VERSION ""

NS_ :

BS_:

BU_: VCU Tester GWM

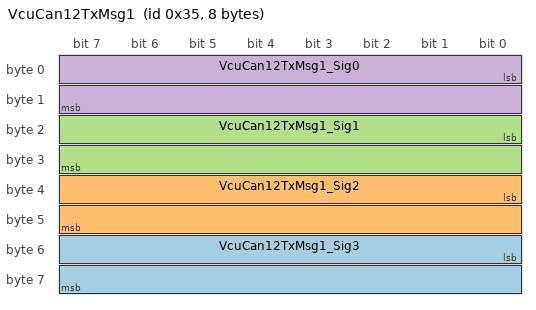
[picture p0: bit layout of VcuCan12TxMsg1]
BO_ 53 VcuCan12TxMsg1: 8 VCU
 SG_ VcuCan12TxMsg1_Sig3 : 48|16@1- (1,0) [0|0] ""  GWM
 SG_ VcuCan12TxMsg1_Sig2 : 32|16@1- (1,0) [0|0] ""  GWM
 SG_ VcuCan12TxMsg1_Sig1 : 16|16@1- (1,0) [0|0] ""  GWM
 SG_ VcuCan12TxMsg1_Sig0 : 0|16@1- (1,0) [0|0] ""  GWM

BO_ 2033 XCP_Response: 8 VCU
 SG_ XCP_Response_Signal : 0|64@1+ (1,0) [0|1.844674407371E+019] ""  Tester

BO_ 2032 XCP_Request: 8 Tester
 SG_ XCP_Request_Signal : 0|64@1+ (1,0) [0|1.844674407371E+019] ""  VCU

BA_DEF_ BO_  "VFrameFormat" ENUM  "StandardCAN","ExtendedCAN","reserved","reserved","reserved","reserved","reserved","reserved","reserved","reserved","reserved","reserved","reserved","reserved","StandardCAN_FD","ExtendedCAN_FD";
BA_DEF_ BO_  "GenMsgCycleTime" INT 0 0;
BA_DEF_ BO_  "GenMsgSendType" ENUM  "Cyclic","NotUsed","NotUsed","NotUsed","NotUsed","NotUsed","NotUsed","IfActive","NoMsgSendType","NotUsed";
BA_DEF_ SG_  "GenSigSendType" ENUM  "Cyclic","OnWrite","OnWriteWithRepetition","OnChange","OnChangeWithRepetition","IfActive","IfActiveWithRepetition","NoSigSendType","NotUsed","NotUsed","NotUsed","NotUsed","NotUsed";
BA_DEF_  "Baudrate" INT 0 1000000;
BA_DEF_  "BusType" STRING ;
BA_DEF_  "Manufacturer" STRING ;
BA_DEF_ BU_  "NodeLayerModules" STRING ;
BA_DEF_  "NmAsrTimeoutTime" INT 1 65535;
BA_DEF_  "NmAsrMessageCount" INT 1 256;
BA_DEF_ BU_  "NmAsrCanMsgReducedTime" INT 1 65535;
BA_DEF_  "NmAsrCanMsgCycleTime" INT 1 65535;
BA_DEF_ BU_  "ILUsed" ENUM  "no","yes";
BA_DEF_ BO_  "GenMsgILSupport" ENUM  "no","yes";
BA_DEF_  "DBName" STRING ;
BA_DEF_DEF_  "VFrameFormat" "ExtendedCAN_FD";
BA_DEF_DEF_  "GenMsgCycleTime" 0;
BA_DEF_DEF_  "GenMsgSendType" "Cyclic";
BA_DEF_DEF_  "GenSigSendType" "Cyclic";
BA_DEF_DEF_  "Baudrate" 500000;
BA_DEF_DEF_  "BusType" "";
BA_DEF_DEF_  "Manufacturer" "Vector";
BA_DEF_DEF_  "NodeLayerModules" " ";
BA_DEF_DEF_  "NmAsrTimeoutTime" 1;
BA_DEF_DEF_  "NmAsrMessageCount" 1;
BA_DEF_DEF_  "NmAsrCanMsgReducedTime" 1;
BA_DEF_DEF_  "NmAsrCanMsgCycleTime" 1;
BA_DEF_DEF_  "ILUsed" "yes";
BA_DEF_DEF_  "GenMsgILSupport" "yes";
BA_DEF_DEF_  "DBName" "";
BA_ "BusType" "CAN";
BA_ "DBName" "ATOM_CAN_XCP";
BA_ "GenMsgCycleTime" BO_ 53 500;
BA_ "VFrameFormat" BO_ 53 0;
BA_ "GenMsgSendType" BO_ 2033 8;
BA_ "GenMsgILSupport" BO_ 2033 0;
BA_ "VFrameFormat" BO_ 2033 0;
BA_ "GenMsgSendType" BO_ 2032 8;
BA_ "GenMsgILSupport" BO_ 2032 0;
BA_ "VFrameFormat" BO_ 2032 0;
